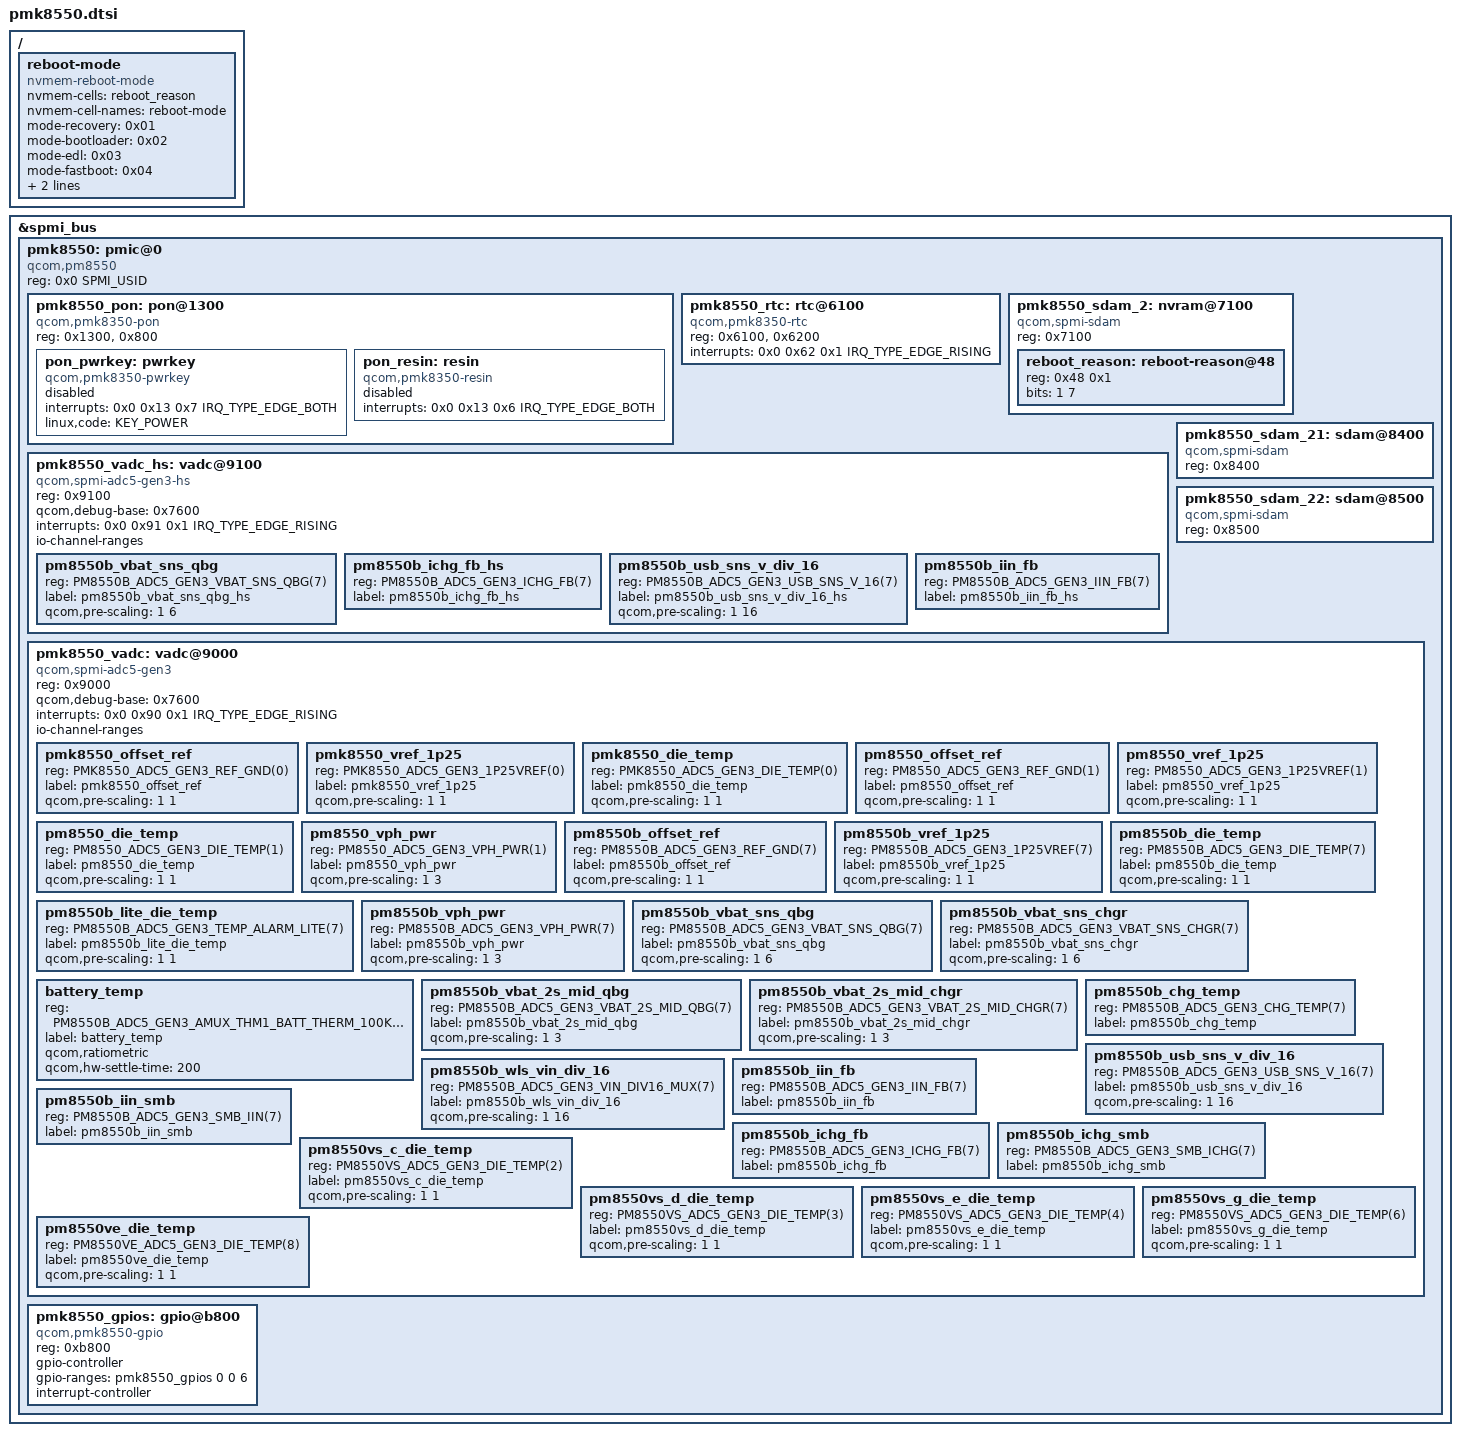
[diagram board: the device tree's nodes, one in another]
// SPDX-License-Identifier: BSD-3-Clause
/*
 * Copyright (c) 2022, Linaro Limited
 */

#include <dt-bindings/input/input.h>
#include <dt-bindings/input/linux-event-codes.h>
#include <dt-bindings/interrupt-controller/irq.h>
#include <dt-bindings/spmi/spmi.h>
#include <dt-bindings/iio/adc/qcom,spmi-adc5-gen3-pmk8550.h>
#include <dt-bindings/iio/adc/qcom,spmi-adc5-gen3-pm8550.h>
#include <dt-bindings/iio/adc/qcom,spmi-adc5-gen3-pm8550b.h>
#include <dt-bindings/iio/adc/qcom,spmi-adc5-gen3-pm8550vx.h>
#include <dt-bindings/iio/adc/qcom,spmi-vadc.h>

#include <dt-bindings/iio/adc/qcom,spmi-adc5-gen3-pmk8550.h>
#include <dt-bindings/iio/adc/qcom,spmi-adc5-gen3-pm8550.h>
#include <dt-bindings/iio/adc/qcom,spmi-adc5-gen3-pm8550b.h>
#define PM8550VE_SID	8
#include <dt-bindings/iio/adc/qcom,spmi-adc5-gen3-pm8550vx.h>
#include <dt-bindings/iio/adc/qcom,spmi-vadc.h>

/ {
	reboot-mode {
		compatible = "nvmem-reboot-mode";
		nvmem-cells = <&reboot_reason>;
		nvmem-cell-names = "reboot-mode";
		mode-recovery = <0x01>;
		mode-bootloader = <0x02>;
		mode-edl = <0x03>;
		mode-fastboot = <0x04>;
		mode-usb = <0x05>;
		mode-initrd = <0x06>;
	};
};

&spmi_bus {
	pmk8550: pmic@0 {
		compatible = "qcom,pm8550", "qcom,spmi-pmic";
		reg = <0x0 SPMI_USID>;
		#address-cells = <1>;
		#size-cells = <0>;

		pmk8550_pon: pon@1300 {
			compatible = "qcom,pmk8350-pon";
			reg = <0x1300>, <0x800>;
			reg-names = "hlos", "pbs";

			pon_pwrkey: pwrkey {
				compatible = "qcom,pmk8350-pwrkey";
				interrupts = <0x0 0x13 0x7 IRQ_TYPE_EDGE_BOTH>;
				linux,code = <KEY_POWER>;
				status = "disabled";
			};

			pon_resin: resin {
				compatible = "qcom,pmk8350-resin";
				interrupts = <0x0 0x13 0x6 IRQ_TYPE_EDGE_BOTH>;
				status = "disabled";
			};
		};

		pmk8550_rtc: rtc@6100 {
			compatible = "qcom,pmk8350-rtc";
			reg = <0x6100>, <0x6200>;
			reg-names = "rtc", "alarm";
			interrupts = <0x0 0x62 0x1 IRQ_TYPE_EDGE_RISING>;
		};

		pmk8550_sdam_2: nvram@7100 {
			compatible = "qcom,spmi-sdam";
			reg = <0x7100>;
			#address-cells = <1>;
			#size-cells = <1>;
			ranges = <0 0x7100 0x100>;

			reboot_reason: reboot-reason@48 {
				reg = <0x48 0x1>;
				bits = <1 7>;
			};
		};

		pmk8550_vadc_hs: vadc@9100 {
			compatible = "qcom,spmi-adc5-gen3-hs";
			reg = <0x9100>;
			qcom,debug-base = <0x7600>;
			#address-cells = <1>;
			#size-cells = <0>;
			interrupt-names = "adc-hs-sdam0";
			interrupts = <0x0 0x91 0x1 IRQ_TYPE_EDGE_RISING>;
			#thermal-sensor-cells = <1>;
			#io-channel-cells = <1>;
			io-channel-ranges;

			status = "okay";

			// The driver is dependent on this order for user space to work correctly. 
			// Please consult with TGoyen before changing
			pm8550b_vbat_sns_qbg {
				reg = <PM8550B_ADC5_GEN3_VBAT_SNS_QBG(7)>;
				label = "pm8550b_vbat_sns_qbg_hs";
				qcom,pre-scaling = <1 6>;
			};

			pm8550b_ichg_fb_hs: pm8550b_ichg_fb_hs {
				reg = <PM8550B_ADC5_GEN3_ICHG_FB(7)>;
				label = "pm8550b_ichg_fb_hs";
			};

			pm8550b_usb_sns_v_div_16 {
				reg = <PM8550B_ADC5_GEN3_USB_SNS_V_16(7)>;
				label = "pm8550b_usb_sns_v_div_16_hs";
				qcom,pre-scaling = <1 16>;
			};

			pm8550b_iin_fb {
				reg = <PM8550B_ADC5_GEN3_IIN_FB(7)>;
				label = "pm8550b_iin_fb_hs";
			};
		};

		pmk8550_sdam_21: sdam@8400 {
				compatible = "qcom,spmi-sdam";
				reg = <0x8400>;

				status = "okay";
		};

		pmk8550_sdam_22: sdam@8500 {
				compatible = "qcom,spmi-sdam";
				reg = <0x8500>;

				status = "okay";
		};

		pmk8550_vadc: vadc@9000 {
			compatible = "qcom,spmi-adc5-gen3";
			reg = <0x9000>;
			qcom,debug-base = <0x7600>;
			#address-cells = <1>;
			#size-cells = <0>;
			interrupt-names = "adc-sdam0";
			interrupts = <0x0 0x90 0x1 IRQ_TYPE_EDGE_RISING>;
			#thermal-sensor-cells = <1>;
			#io-channel-cells = <1>;
			io-channel-ranges;

			/* PMK8550 Channel nodes */
			pmk8550_offset_ref {
				reg = <PMK8550_ADC5_GEN3_REF_GND(0)>;
				label = "pmk8550_offset_ref";
				qcom,pre-scaling = <1 1>;
			};

			pmk8550_vref_1p25 {
				reg = <PMK8550_ADC5_GEN3_1P25VREF(0)>;
				label = "pmk8550_vref_1p25";
				qcom,pre-scaling = <1 1>;
			};

			pmk8550_die_temp {
				reg = <PMK8550_ADC5_GEN3_DIE_TEMP(0)>;
				label = "pmk8550_die_temp";
				qcom,pre-scaling = <1 1>;
			};

			/* PM8550 Channel nodes */
			pm8550_offset_ref {
				reg = <PM8550_ADC5_GEN3_REF_GND(1)>;
				label = "pm8550_offset_ref";
				qcom,pre-scaling = <1 1>;
			};

			pm8550_vref_1p25 {
				reg = <PM8550_ADC5_GEN3_1P25VREF(1)>;
				label = "pm8550_vref_1p25";
				qcom,pre-scaling = <1 1>;
			};

			pm8550_die_temp {
				reg = <PM8550_ADC5_GEN3_DIE_TEMP(1)>;
				label = "pm8550_die_temp";
				qcom,pre-scaling = <1 1>;
			};

			pm8550_vph_pwr {
				reg = <PM8550_ADC5_GEN3_VPH_PWR(1)>;
				label = "pm8550_vph_pwr";
				qcom,pre-scaling = <1 3>;
			};

			/* PM8550B Channel nodes */
			pm8550b_offset_ref {
				reg = <PM8550B_ADC5_GEN3_REF_GND(7)>;
				label = "pm8550b_offset_ref";
				qcom,pre-scaling = <1 1>;
			};

			pm8550b_vref_1p25 {
				reg = <PM8550B_ADC5_GEN3_1P25VREF(7)>;
				label = "pm8550b_vref_1p25";
				qcom,pre-scaling = <1 1>;
			};

			pm8550b_die_temp {
				reg = <PM8550B_ADC5_GEN3_DIE_TEMP(7)>;
				label = "pm8550b_die_temp";
				qcom,pre-scaling = <1 1>;
			};

			pm8550b_lite_die_temp {
				reg = <PM8550B_ADC5_GEN3_TEMP_ALARM_LITE(7)>;
				label = "pm8550b_lite_die_temp";
				qcom,pre-scaling = <1 1>;
			};

			pm8550b_vph_pwr {
				reg = <PM8550B_ADC5_GEN3_VPH_PWR(7)>;
				label = "pm8550b_vph_pwr";
				qcom,pre-scaling = <1 3>;
			};

			pm8550b_vbat_sns_qbg {
				reg = <PM8550B_ADC5_GEN3_VBAT_SNS_QBG(7)>;
				label = "pm8550b_vbat_sns_qbg";
				qcom,pre-scaling = <1 6>;
			};

			pm8550b_vbat_sns_chgr {
				reg = <PM8550B_ADC5_GEN3_VBAT_SNS_CHGR(7)>;
				label = "pm8550b_vbat_sns_chgr";
				qcom,pre-scaling = <1 6>;
			};

			// NOTE That this seems correct, but is not... TGoyen
			// qcom,scale-fn-type = <ADC_SCALE_HW_CALIB_PM5_GEN3_BATT_THERM_100K>;
			battery_temp {
				reg = <PM8550B_ADC5_GEN3_AMUX_THM1_BATT_THERM_100K_PU(7)>;
				label = "battery_temp";
                qcom,ratiometric;
                qcom,hw-settle-time = <200>;
			};

			pm8550b_vbat_2s_mid_qbg {
				reg = <PM8550B_ADC5_GEN3_VBAT_2S_MID_QBG(7)>;
				label = "pm8550b_vbat_2s_mid_qbg";
				qcom,pre-scaling = <1 3>;
			};

			pm8550b_vbat_2s_mid_chgr {
				reg = <PM8550B_ADC5_GEN3_VBAT_2S_MID_CHGR(7)>;
				label = "pm8550b_vbat_2s_mid_chgr";
				qcom,pre-scaling = <1 3>;
			};

			pm8550b_chg_temp {
				reg = <PM8550B_ADC5_GEN3_CHG_TEMP(7)>;
				label = "pm8550b_chg_temp";
			};

			pm8550b_usb_sns_v_div_16 {
				reg = <PM8550B_ADC5_GEN3_USB_SNS_V_16(7)>;
				label = "pm8550b_usb_sns_v_div_16";
				qcom,pre-scaling = <1 16>;
			};

			pm8550b_wls_vin_div_16 {
				reg = <PM8550B_ADC5_GEN3_VIN_DIV16_MUX(7)>;
				label = "pm8550b_wls_vin_div_16";
				qcom,pre-scaling = <1 16>;
			};

			// TODO Check Scaling of these
			pm8550b_iin_fb {
				reg = <PM8550B_ADC5_GEN3_IIN_FB(7)>;
				label = "pm8550b_iin_fb";
			};

			pm8550b_iin_smb {
				reg = <PM8550B_ADC5_GEN3_SMB_IIN(7)>;
				label = "pm8550b_iin_smb";
			};

			pm8550b_ichg_fb {
				reg = <PM8550B_ADC5_GEN3_ICHG_FB(7)>;
				label = "pm8550b_ichg_fb";
			};

			pm8550b_ichg_smb {
				reg = <PM8550B_ADC5_GEN3_SMB_ICHG(7)>;
				label = "pm8550b_ichg_smb";
			};

			/* PM8550VS_C Channel nodes */
			pm8550vs_c_die_temp {
				reg = <PM8550VS_ADC5_GEN3_DIE_TEMP(2)>;
				label = "pm8550vs_c_die_temp";
				qcom,pre-scaling = <1 1>;
			};

			/* PM8550VS_D Channel nodes */
			pm8550vs_d_die_temp {
				reg = <PM8550VS_ADC5_GEN3_DIE_TEMP(3)>;
				label = "pm8550vs_d_die_temp";
				qcom,pre-scaling = <1 1>;
			};

			/* PM8550VS_E Channel nodes */
			pm8550vs_e_die_temp {
				reg = <PM8550VS_ADC5_GEN3_DIE_TEMP(4)>;
				label = "pm8550vs_e_die_temp";
				qcom,pre-scaling = <1 1>;
			};

			/* PM8550VS_G Channel nodes */
			pm8550vs_g_die_temp {
				reg = <PM8550VS_ADC5_GEN3_DIE_TEMP(6)>;
				label = "pm8550vs_g_die_temp";
				qcom,pre-scaling = <1 1>;
			};

			/* PM8550VE Channel nodes */
			pm8550ve_die_temp {
				reg = <PM8550VE_ADC5_GEN3_DIE_TEMP(8)>;
				label = "pm8550ve_die_temp";
				qcom,pre-scaling = <1 1>;
			};
		};

		pmk8550_gpios: gpio@b800 {
			compatible = "qcom,pmk8550-gpio", "qcom,spmi-gpio";
			reg = <0xb800>;
			gpio-controller;
			gpio-ranges = <&pmk8550_gpios 0 0 6>;
			#gpio-cells = <2>;
			interrupt-controller;
			#interrupt-cells = <2>;
		};
	};
};
